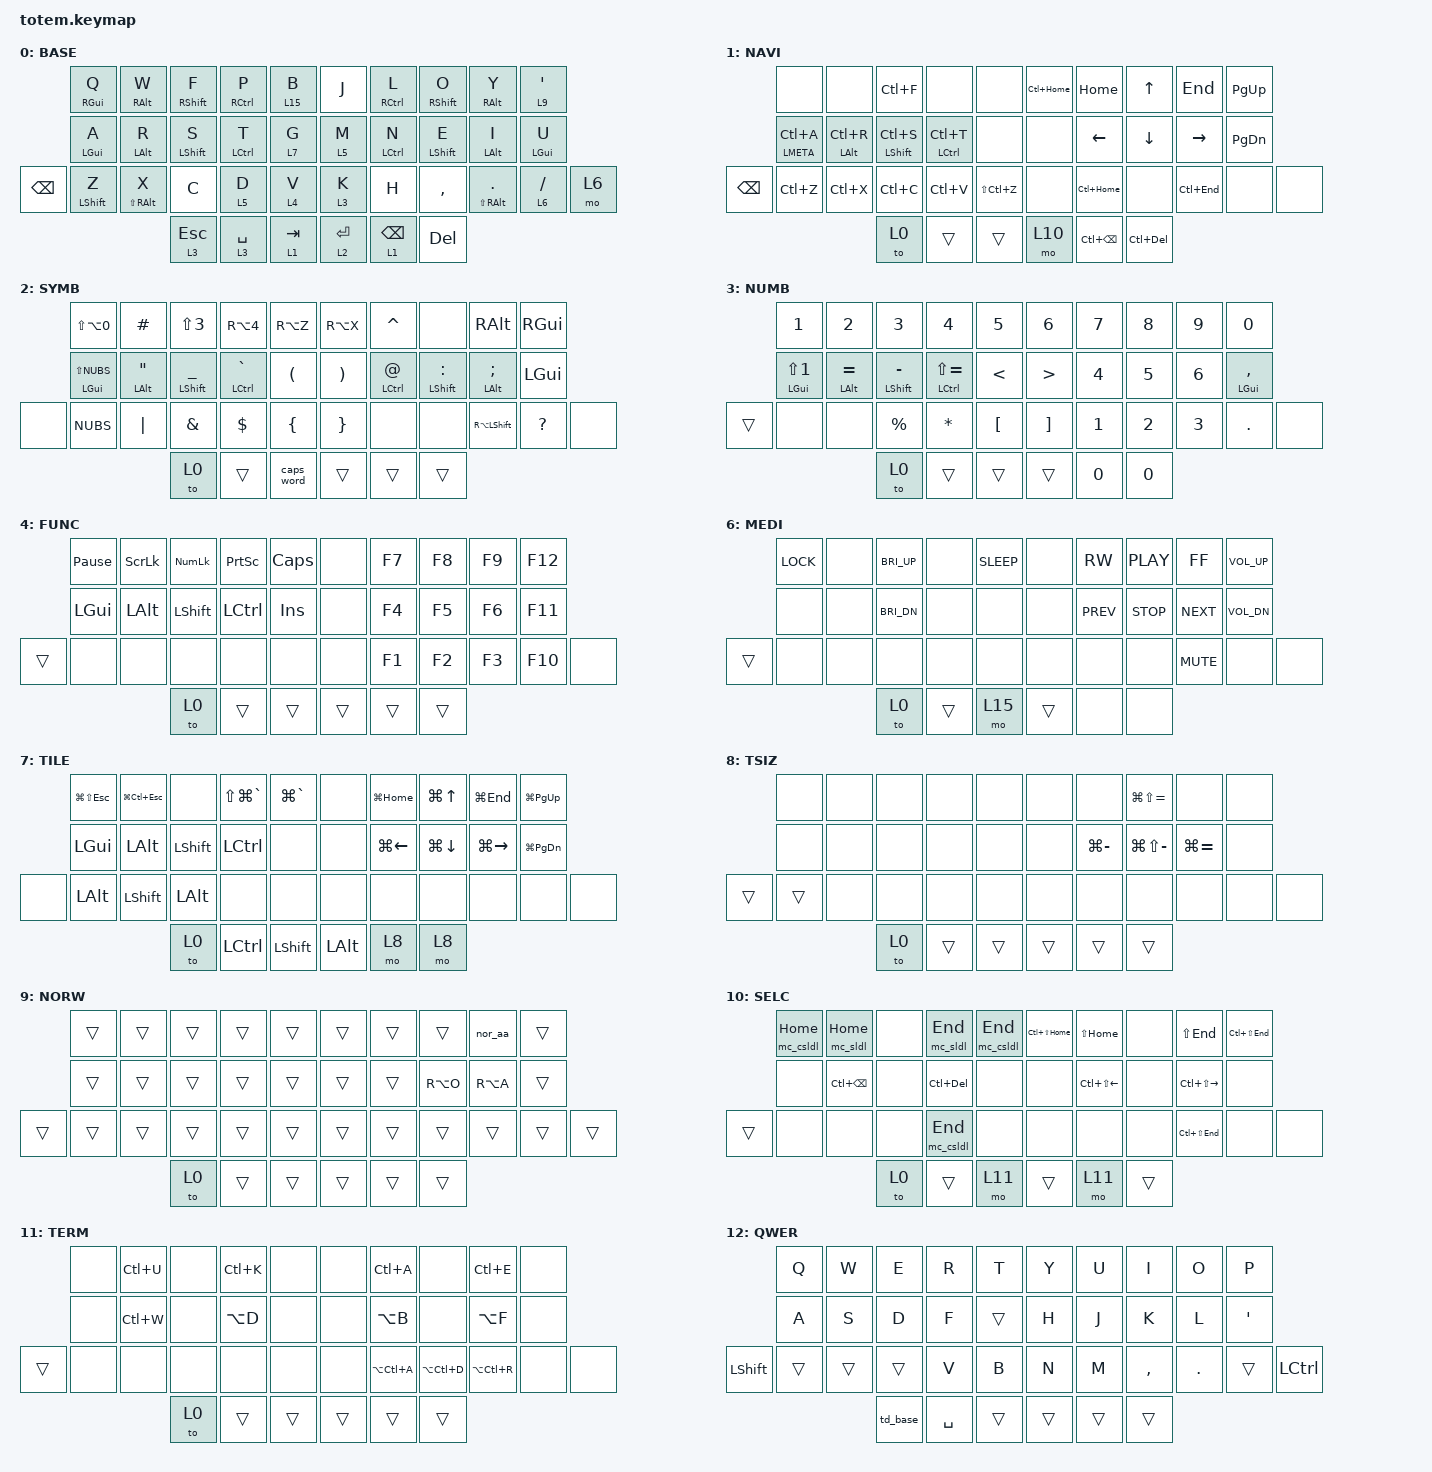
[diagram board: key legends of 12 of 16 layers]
//
//                                                        ▀▀▀▀▀     ▀▀▀▀▀          ▀▀█▀▀
//                                                        ▄▀▀▀▄  ▄  ▄▀▀▀▄  ▄  ▄▀▀▀▄  █  ▄▀▀▀▄
//                                                        █   █  █  █   █  █  █   █  █  █   █
//                                                         ▀▀▀   █   ▀▀▀   █   ▀▀▀   ▀   ▀▀▀
//                                                               █      ▄▄▄█▄▄▄    █   █
//                                                               ▀      █  █  █     █▄█
//                                                             ▀▀▀▀▀    █  █  █      ▀
//                                                                      ▀  ▀  ▀
//
// ▄▄▄▄▄▄▄▄▄▄▄▄▄▄▄▄▄▄▄▄▄▄▄▄▄▄▄▄▄▄▄▄▄▄▄▄▄▄▄▄▄▄▄▄▄▄▄▄▄▄▄▄▄▄▄▄▄▄▄▄▄▄▄▄▄▄▄▄▄▄▄▄▄▄▄▄▄▄▄▄▄▄▄▄▄▄▄▄▄▄▄▄▄▄▄▄▄▄▄▄▄▄▄▄▄▄▄▄▄▄▄▄▄▄▄▄▄▄▄▄▄▄▄▄▄▄▄▄▄▄▄▄▄▄▄▄▄▄▄▄▄▄▄▄▄▄▄▄▄

#include <behaviors.dtsi>
#include <dt-bindings/zmk/bt.h>
#include <dt-bindings/zmk/keys.h>
#include <dt-bindings/zmk/outputs.h>

#define BASE 0
#define NAVI 1
#define SYMB 2
#define NUMB 3
#define FUNC 4
#define CODE 5
#define MEDI 6
#define TILE 7
#define TSIZ 8
#define NORW 9
#define SELC 10
#define TERM 11
#define QWER 12
#define GAME 13
#define CSPL 14
#define BLUE 15

&mt {
    //   retro-tap;

    quick-tap-ms = <325>;
    global-quick-tap;
    flavor = "tap-preferred";
    tapping-term-ms = <250>;
    require-prior-idle-ms = <125>;
};

&lt {
    tapping-term-ms = <150>;
    quick-tap-ms = <225>;
};

/ {
    behaviors {
        hml: homerow_left {
            compatible = "zmk,behavior-hold-tap";
            #binding-cells = <2>;
            tapping-term-ms = <100>;
            quick-tap-ms = <200>;
            flavor = "tap-unless-interrupted";

            //      flavor = "tap-preferred";

            bindings = <&kp>, <&kp>;

            hold-trigger-key-positions = <5 6 7 8 9 15 16 17 18 19 26 27 28 29 30 31 35 36 37>;
        };

        hmr: homerow_right {
            compatible = "zmk,behavior-hold-tap";
            #binding-cells = <2>;
            tapping-term-ms = <150>;
            quick-tap-ms = <0>;
            flavor = "tap-preferred";
            bindings = <&kp>, <&kp>;

            hold-trigger-key-positions = <0 1 2 3 4 10 11 12 13 14 20 21 22 23 24 25 32 33 34>;
        };

        td_lcsh: tap_shift_lock {
            compatible = "zmk,behavior-tap-dance";
            #binding-cells = <0>;
            tapping-term-ms = <200>;
            bindings = <&mo 6>, <&kp K_LOCK>;
        };

        mt_split: mod_tap_split {
            compatible = "zmk,behavior-hold-tap";
            label = "MT_SPLIT";
            #binding-cells = <2>;
            tapping-term-ms = <200>;
            quick-tap-ms = <0>;
            flavor = "hold-preferred";
            bindings = <&codspl>, <&kp>;
        };

        td_base: tap_dance_base_esc {
            compatible = "zmk,behavior-tap-dance";
            #binding-cells = <0>;
            tapping-term-ms = <200>;
            bindings = <&kp ESC>, <&to 0>;
        };
    };

    macros {
        vsc: macro_vscode_cmd {
            #binding-cells = <1>;
            compatible = "zmk,behavior-macro-one-param";
            bindings =
                <&macro_tap>,
                <&kp LC(K) &macro_param_1to1>,
                <&macro_tap>,
                <&kp MACRO_PLACEHOLDER>;
        };

        codspl: macro_vscode_split {
            #binding-cells = <1>;
            compatible = "zmk,behavior-macro-one-param";
            bindings =
                <&macro_tap>,
                <&kp LC(K) &macro_param_1to1>,
                <&macro_tap>,
                <&kp MACRO_PLACEHOLDER>;
        };

        mc_rm2: macro_rmeta2 {
            compatible = "zmk,behavior-macro-two-param";
            #binding-cells = <2>;
            bindings =
                <&macro_press>,
                <&kp RGUI &macro_param_1to1>,
                <&macro_tap>,
                <&kp MACRO_PLACEHOLDER>,
                <&macro_release>,
                <&kp RGUI &macro_param_2to1>,
                <&macro_tap>,
                <&kp MACRO_PLACEHOLDER>;
        };

        mc_sldl: macro_select_delete {
            compatible = "zmk,behavior-macro-one-param";
            #binding-cells = <1>;
            bindings =
                <&macro_press>,
                <&kp LSHFT &macro_param_1to1>,
                <&macro_tap>,
                <&kp MACRO_PLACEHOLDER>,
                <&macro_release>,
                <&kp LSHFT>,
                <&macro_tap>,
                <&kp DEL>;
        };

        mc_csldl: macro_ctrsel_del {
            compatible = "zmk,behavior-macro-one-param";
            #binding-cells = <1>;
            bindings =
                <&macro_press>,
                <&kp LSHFT>,
                <&macro_press>,
                <&kp LCTRL &macro_param_1to1>,
                <&macro_tap>,
                <&kp MACRO_PLACEHOLDER>,
                <&macro_release>,
                <&kp LCTRL>,
                <&macro_release>,
                <&kp LSHFT>,
                <&macro_tap>,
                <&kp DEL>;
        };

        nor_aa: nor_aa {
            compatible = "zmk,behavior-macro";
            #binding-cells = <0>;
            bindings = <&macro_tap>, <&kp LS(RA(LEFT_BRACKET)) &kp A>;

            label = "NOR_AA";
        };
    };

    combos {
        compatible = "zmk,combos";

        combo_esc {
            bindings = <&kp ESC>;
            key-positions = <0 1>;
        };
    };

    keymap {
        compatible = "zmk,keymap";

        // ▄▄▄▄▄▄▄▄▄▄▄▄▄▄▄▄▄▄▄▄▄▄▄▄▄▄▄▄▄▄▄▄▄▄▄▄▄▄▄▄▄▄▄▄▄▄▄▄▄▄▄▄▄▄▄▄▄▄▄▄▄▄▄▄▄▄▄▄▄▄▄▄▄▄▄▄▄▄▄▄▄▄▄▄▄▄▄▄▄▄▄▄▄▄▄▄▄▄▄▄▄▄▄▄▄▄▄▄▄▄▄▄▄▄▄▄▄▄▄▄▄▄▄▄▄▄▄▄▄▄▄▄▄▄▄▄▄▄▄▄▄▄▄▄▄▄▄▄▄

        base_layer {
            // ┏━━━━━━━━━━━━━━━━━━━━━━━━━━━━━━━━━━━━━━━┓

            label = "BASE";

            // ┗━━━━━━━━━━━━━━━━━━━━━━━━━━━━━━━━━━━━━━━┛
            //             ┏━━━━━━━━━━━┳━━━━━━━━━━━┳━━━━━━━━━━━┳━━━━━━━━━━━┳━━━━━━━━━━━┓   ┏━━━━━━━━━━━┳━━━━━━━━━━━┳━━━━━━━━━━━┳━━━━━━━━━━━┳━━━━━━━━━━━┓
            //             ┃     Q     ┃     W     ┃     F     ┃     P     ┃     B     ┃   ┃     J     ┃     L     ┃     O     ┃     Y     ┃     '     ┃
            //             ┣━━━━━━━━━━━╋━━━━━━━━━━━╋━━━━━━━━━━━╋━━━━━━━━━━━╋━━━━━━━━━━━┫   ┣━━━━━━━━━━━╋━━━━━━━━━━━╋━━━━━━━━━━━╋━━━━━━━━━━━╋━━━━━━━━━━━┫
            //             ┃     A     ┃     R     ┃     S     ┃     T     ┃     G     ┃   ┃     M     ┃     N     ┃     E     ┃     I     ┃     U     ┃
            // ┏━━━━━━━━━━━╋━━━━━━━━━━━╋━━━━━━━━━━━╋━━━━━━━━━━━╋━━━━━━━━━━━╋━━━━━━━━━━━┫   ┣━━━━━━━━━━━╋━━━━━━━━━━━╋━━━━━━━━━━━╋━━━━━━━━━━━╋━━━━━━━━━━━╋━━━━━━━━━━━┓
            // ┃    BSPC   ┃     Z     ┃     X     ┃     C     ┃     D     ┃     V     ┃   ┃     K     ┃     H     ┃     ,     ┃     .     ┃     /     ┃           ┃
            // ┗━━━━━━━━━━━┻━━━━━━━━━━━┻━━━━━━━━━━━╋━━━━━━━━━━━╋━━━━━━━━━━━╋━━━━━━━━━━━┫   ┣━━━━━━━━━━━╋━━━━━━━━━━━╋━━━━━━━━━━━╋━━━━━━━━━━━┻━━━━━━━━━━━┻━━━━━━━━━━━┛
            //                                     ┃    ESC    ┃    SPC    ┃    TAB    ┃   ┃   ENTER   ┃    BSPC   ┃    DEL    ┃
            //                                     ┗━━━━━━━━━━━┻━━━━━━━━━━━┻━━━━━━━━━━━┛   ┗━━━━━━━━━━━┻━━━━━━━━━━━┻━━━━━━━━━━━┛
            //             ┏━━━━━━━━━━━┳━━━━━━━━━━━┳━━━━━━━━━━━┳━━━━━━━━━━━┳━━━━━━━━━━━┓   ┏━━━━━━━━━━━┳━━━━━━━━━━━┳━━━━━━━━━━━┳━━━━━━━━━━━┳━━━━━━━━━━━┓
            //             ┃   RMETA   ┃   RALT    ┃   RSHFT   ┃   RCTRL   ┃           ┃   ┃           ┃   RCTRL   ┃   RSHFT   ┃    RALT   ┃    NORW   ┃
            //             ┣━━━━━━━━━━━╋━━━━━━━━━━━╋━━━━━━━━━━━╋━━━━━━━━━━━╋━━━━━━━━━━━┫   ┣━━━━━━━━━━━╋━━━━━━━━━━━╋━━━━━━━━━━━╋━━━━━━━━━━━╋━━━━━━━━━━━┫
            //             ┃   LMETA   ┃   LALT   ┃   LSHFT   ┃   LCTRL    ┃    CODE   ┃   ┃   CODE    ┃   LCTRL    ┃   LSHFT   ┃   LALT   ┃   LMETA   ┃
            // ┏━━━━━━━━━━━╋━━━━━━━━━━━╋━━━━━━━━━━━╋━━━━━━━━━━━╋━━━━━━━━━━━╋━━━━━━━━━━━┫   ┣━━━━━━━━━━━╋━━━━━━━━━━━╋━━━━━━━━━━━╋━━━━━━━━━━━╋━━━━━━━━━━━╋━━━━━━━━━━━┓
            // ┃   LSHFT   ┃           ┃   COMP    ┃           ┃   TILE    ┃    FUN    ┃   ┃           ┃           ┃           ┃    COMP   ┃           ┃   MEDI    ┃
            // ┗━━━━━━━━━━━┻━━━━━━━━━━━┻━━━━━━━━━━━╋━━━━━━━━━━━╋━━━━━━━━━━━╋━━━━━━━━━━━┫   ┣━━━━━━━━━━━╋━━━━━━━━━━━╋━━━━━━━━━━━╋━━━━━━━━━━━┻━━━━━━━━━━━┻━━━━━━━━━━━┛
            //                                     ┃           ┃    NUM    ┃    NAV    ┃   ┃    SYM    ┃   LSHFT   ┃           ┃
            //                                     ┗━━━━━━━━━━━┻━━━━━━━━━━━┻━━━━━━━━━━━┛   ┗━━━━━━━━━━━┻━━━━━━━━━━━┻━━━━━━━━━━━┛

            bindings = <
               &mt RGUI Q        &mt RALT W      &mt RSHFT F   &mt RCTRL P  &lt 15 B     &kp J      &mt RCTRL L      &mt RSHFT O  &mt RALT Y        &lt 9 SQT
               &mt LGUI A        &mt LALT R      &mt LSHFT S   &mt LCTRL T  &lt 7 G      &lt 5 M    &mt LCTRL N      &mt LSHFT E  &mt LALT I        &mt LGUI U
&kp BACKSPACE  &mt LEFT_SHIFT Z  &mt LS(RALT) X  &kp C         &lt 5 D      &lt 4 V      &lt 3 K    &kp H            &kp COMMA    &mt LS(RALT) DOT  &lt 6 FSLH  &mo 6
                                                 &lt 3 ESCAPE  &lt 3 SPACE  &lt 1 TAB    &lt 2 RET  &lt 1 BACKSPACE  &kp DEL
            >;
        };

        // ▄▄▄▄▄▄▄▄▄▄▄▄▄▄▄▄▄▄▄▄▄▄▄▄▄▄▄▄▄▄▄▄▄▄▄▄▄▄▄▄▄▄▄▄▄▄▄▄▄▄▄▄▄▄▄▄▄▄▄▄▄▄▄▄▄▄▄▄▄▄▄▄▄▄▄▄▄▄▄▄▄▄▄▄▄▄▄▄▄▄▄▄▄▄▄▄▄▄▄▄▄▄▄▄▄▄▄▄▄▄▄▄▄▄▄▄▄▄▄▄▄▄▄▄▄▄▄▄▄▄▄▄▄▄▄▄▄▄▄▄▄▄▄▄▄▄▄▄▄

        nav_layer {
            // ┏━━━━━━━━━━━━━━━━━━━━━━━━━━━━━━━━━━━━━━━┓

            label = "NAVI";

            // ┗━━━━━━━━━━━━━━━━━━━━━━━━━━━━━━━━━━━━━━━┛
            //             ┏━━━━━━━━━━━┳━━━━━━━━━━━┳━━━━━━━━━━━┳━━━━━━━━━━━┳━━━━━━━━━━━┓   ┏━━━━━━━━━━━┳━━━━━━━━━━━┳━━━━━━━━━━━┳━━━━━━━━━━━┳━━━━━━━━━━━┓
            //             ┃           ┃           ┃    FIND   ┃           ┃           ┃   ┃    TOP    ┃   HOME    ┃    UP     ┃   END     ┃   PG_UP   ┃
            //             ┣━━━━━━━━━━━╋━━━━━━━━━━━╋━━━━━━━━━━━╋━━━━━━━━━━━╋━━━━━━━━━━━┫   ┣━━━━━━━━━━━╋━━━━━━━━━━━╋━━━━━━━━━━━╋━━━━━━━━━━━╋━━━━━━━━━━━┫
            //             ┃   SELECT  ┃   RELOAD  ┃    SAVE   ┃  NEW TAB  ┃ CAPS WORD ┃   ┃           ┃   LEFT    ┃    DOWN   ┃   RIGHT   ┃   PG_DN   ┃
            // ┏━━━━━━━━━━━╋━━━━━━━━━━━╋━━━━━━━━━━━╋━━━━━━━━━━━╋━━━━━━━━━━━╋━━━━━━━━━━━┫   ┣━━━━━━━━━━━╋━━━━━━━━━━━╋━━━━━━━━━━━╋━━━━━━━━━━━╋━━━━━━━━━━━╋━━━━━━━━━━━┓
            // ┃ BACKSPACE ┃    UNDO   ┃    CUT    ┃   COPY    ┃   PASTE   ┃   REDO    ┃   ┃           ┃    TOP    ┃           ┃   BTTM    ┃           ┃           ┃
            // ┗━━━━━━━━━━━┻━━━━━━━━━━━┻━━━━━━━━━━━╋━━━━━━━━━━━╋━━━━━━━━━━━╋━━━━━━━━━━━┫   ┣━━━━━━━━━━━╋━━━━━━━━━━━╋━━━━━━━━━━━╋━━━━━━━━━━━┻━━━━━━━━━━━┻━━━━━━━━━━━┛
            //                                     ┃           ┃           ┃           ┃   ┃   SELECT  ┃^BACKSPACE ┃   ^ DEL   ┃
            //                                     ┗━━━━━━━━━━━┻━━━━━━━━━━━┻━━━━━━━━━━━┛   ┗━━━━━━━━━━━┻━━━━━━━━━━━┻━━━━━━━━━━━┛

            bindings = <
          &none            &none           &kp LC(F)        &none            &none            &kp LC(HOME)  &kp HOME      &kp UP       &kp END      &kp PG_UP
          &mt LMETA LC(A)  &mt LALT LC(R)  &mt LSHFT LC(S)  &mt LCTRL LC(T)  &none            &none         &kp LEFT      &kp DOWN     &kp RIGHT    &kp PG_DN
&kp BSPC  &kp LC(Z)        &kp LC(X)       &kp LC(C)        &kp LC(V)        &kp LS(LC(Z))    &none         &kp LC(HOME)  &none        &kp LC(END)  &none      &none
                                           &to 0            &trans           &trans           &mo 10        &kp LC(BSPC)  &kp LC(DEL)
            >;
        };

        // ▄▄▄▄▄▄▄▄▄▄▄▄▄▄▄▄▄▄▄▄▄▄▄▄▄▄▄▄▄▄▄▄▄▄▄▄▄▄▄▄▄▄▄▄▄▄▄▄▄▄▄▄▄▄▄▄▄▄▄▄▄▄▄▄▄▄▄▄▄▄▄▄▄▄▄▄▄▄▄▄▄▄▄▄▄▄▄▄▄▄▄▄▄▄▄▄▄▄▄▄▄▄▄▄▄▄▄▄▄▄▄▄▄▄▄▄▄▄▄▄▄▄▄▄▄▄▄▄▄▄▄▄▄▄▄▄▄▄▄▄▄▄▄▄▄▄▄▄▄

        symbol_layer {
            // ┏━━━━━━━━━━━━━━━━━━━━━━━━━━━━━━━━━━━━━━━┓

            label = "SYMB";

            // ┗━━━━━━━━━━━━━━━━━━━━━━━━━━━━━━━━━━━━━━━┛
            //             ┏━━━━━━━━━━━┳━━━━━━━━━━━┳━━━━━━━━━━━┳━━━━━━━━━━━┳━━━━━━━━━━━┓   ┏━━━━━━━━━━━┳━━━━━━━━━━━┳━━━━━━━━━━━┳━━━━━━━━━━━┳━━━━━━━━━━━┓
            //             ┃     °     ┃     #     ┃     £     ┃     ˆ     ┃     «     ┃   ┃     »     ┃           ┃           ┃           ┃           ┃
            //             ┣━━━━━━━━━━━╋━━━━━━━━━━━╋━━━━━━━━━━━╋━━━━━━━━━━━╋━━━━━━━━━━━┫   ┣━━━━━━━━━━━╋━━━━━━━━━━━╋━━━━━━━━━━━╋━━━━━━━━━━━╋━━━━━━━━━━━┫
            //             ┃     |     ┃     @     ┃     _     ┃     `     ┃     (     ┃   ┃     )     ┃     "     ┃     :     ┃     ;     ┃           ┃
            // ┏━━━━━━━━━━━╋━━━━━━━━━━━╋━━━━━━━━━━━╋━━━━━━━━━━━╋━━━━━━━━━━━╋━━━━━━━━━━━┫   ┣━━━━━━━━━━━╋━━━━━━━━━━━╋━━━━━━━━━━━╋━━━━━━━━━━━╋━━━━━━━━━━━╋━━━━━━━━━━━┓
            // ┃           ┃     \     ┃     ~     ┃     &     ┃     $     ┃     {     ┃   ┃     }     ┃           ┃           ┃           ┃     ?     ┃           ┃
            // ┗━━━━━━━━━━━┻━━━━━━━━━━━┻━━━━━━━━━━━╋━━━━━━━━━━━╋━━━━━━━━━━━╋━━━━━━━━━━━┫   ┣━━━━━━━━━━━╋━━━━━━━━━━━╋━━━━━━━━━━━╋━━━━━━━━━━━┻━━━━━━━━━━━┻━━━━━━━━━━━┛
            //                                     ┃           ┃           ┃           ┃   ┃           ┃           ┃           ┃
            //                                     ┗━━━━━━━━━━━┻━━━━━━━━━━━┻━━━━━━━━━━━┛   ┗━━━━━━━━━━━┻━━━━━━━━━━━┻━━━━━━━━━━━┛

            bindings = <
       &kp LS(LA(0))      &kp HASH      &kp LS(NUMBER_3)  &kp RA(NUMBER_4)  &kp RA(Z)     &kp RA(X)  &kp CARET     &none            &kp RALT       &kp RGUI
       &mt LGUI LS(NUBS)  &mt LALT DQT  &mt LSHFT UNDER   &mt LCTRL GRAVE   &kp LPAR      &kp RPAR   &mt LCTRL AT  &mt LSHFT COLON  &mt LALT SEMI  &kp LGUI
&none  &kp NUBS           &kp PIPE      &kp AMPS          &kp DLLR          &kp LBRC      &kp RBRC   &none         &none            &kp RA(LSHFT)  &kp QMARK  &none
                                        &to 0             &trans            &caps_word    &trans     &trans        &trans
            >;
        };

        // ▄▄▄▄▄▄▄▄▄▄▄▄▄▄▄▄▄▄▄▄▄▄▄▄▄▄▄▄▄▄▄▄▄▄▄▄▄▄▄▄▄▄▄▄▄▄▄▄▄▄▄▄▄▄▄▄▄▄▄▄▄▄▄▄▄▄▄▄▄▄▄▄▄▄▄▄▄▄▄▄▄▄▄▄▄▄▄▄▄▄▄▄▄▄▄▄▄▄▄▄▄▄▄▄▄▄▄▄▄▄▄▄▄▄▄▄▄▄▄▄▄▄▄▄▄▄▄▄▄▄▄▄▄▄▄▄▄▄▄▄▄▄▄▄▄▄▄▄▄

        number_layer {
            // ┏━━━━━━━━━━━━━━━━━━━━━━━━━━━━━━━━━━━━━━━┓

            label = "NUMB";

            // ┗━━━━━━━━━━━━━━━━━━━━━━━━━━━━━━━━━━━━━━━┛
            //             ┏━━━━━━━━━━━┳━━━━━━━━━━━┳━━━━━━━━━━━┳━━━━━━━━━━━┳━━━━━━━━━━━┓   ┏━━━━━━━━━━━┳━━━━━━━━━━━┳━━━━━━━━━━━┳━━━━━━━━━━━┳━━━━━━━━━━━┓
            //             ┃     1     ┃     2     ┃     3     ┃     4     ┃     5     ┃   ┃     6     ┃     7     ┃     8     ┃     9     ┃     0     ┃
            //             ┣━━━━━━━━━━━╋━━━━━━━━━━━╋━━━━━━━━━━━╋━━━━━━━━━━━╋━━━━━━━━━━━┫   ┣━━━━━━━━━━━╋━━━━━━━━━━━╋━━━━━━━━━━━╋━━━━━━━━━━━╋━━━━━━━━━━━┫
            //             ┃     !     ┃     =     ┃     -     ┃     +     ┃     <     ┃   ┃     >     ┃     4     ┃     5     ┃     6     ┃           ┃
            // ┏━━━━━━━━━━━╋━━━━━━━━━━━╋━━━━━━━━━━━╋━━━━━━━━━━━╋━━━━━━━━━━━╋━━━━━━━━━━━┫   ┣━━━━━━━━━━━╋━━━━━━━━━━━╋━━━━━━━━━━━╋━━━━━━━━━━━╋━━━━━━━━━━━╋━━━━━━━━━━━┓
            // ┃           ┃           ┃           ┃     %     ┃     *     ┃     [     ┃   ┃     ]     ┃     1     ┃     2     ┃     3     ┃     .     ┃     ,     ┃
            // ┗━━━━━━━━━━━┻━━━━━━━━━━━┻━━━━━━━━━━━╋━━━━━━━━━━━╋━━━━━━━━━━━╋━━━━━━━━━━━┫   ┣━━━━━━━━━━━╋━━━━━━━━━━━╋━━━━━━━━━━━╋━━━━━━━━━━━┻━━━━━━━━━━━┻━━━━━━━━━━━┛
            //                                     ┃           ┃           ┃           ┃   ┃           ┃     0     ┃     0     ┃
            //                                     ┗━━━━━━━━━━━┻━━━━━━━━━━━┻━━━━━━━━━━━┛   ┗━━━━━━━━━━━┻━━━━━━━━━━━┻━━━━━━━━━━━┛

            bindings = <
        &kp N1           &kp N2          &kp N3           &kp N4               &kp N5              &kp N6             &kp N7  &kp N8  &kp N9  &kp N0
        &mt LGUI LS(N1)  &mt LALT EQUAL  &mt LSHFT MINUS  &mt LCTRL LS(EQUAL)  &kp LT              &kp GT             &kp N4  &kp N5  &kp N6  &mt LGUI COMMA
&trans  &none            &none           &kp PERCENT      &kp STAR             &kp LEFT_BRACKET    &kp RIGHT_BRACKET  &kp N1  &kp N2  &kp N3  &kp DOT         &none
                                         &to 0            &trans               &trans              &trans             &kp N0  &kp N0
            >;
        };

        // ▄▄▄▄▄▄▄▄▄▄▄▄▄▄▄▄▄▄▄▄▄▄▄▄▄▄▄▄▄▄▄▄▄▄▄▄▄▄▄▄▄▄▄▄▄▄▄▄▄▄▄▄▄▄▄▄▄▄▄▄▄▄▄▄▄▄▄▄▄▄▄▄▄▄▄▄▄▄▄▄▄▄▄▄▄▄▄▄▄▄▄▄▄▄▄▄▄▄▄▄▄▄▄▄▄▄▄▄▄▄▄▄▄▄▄▄▄▄▄▄▄▄▄▄▄▄▄▄▄▄▄▄▄▄▄▄▄▄▄▄▄▄▄▄▄▄▄▄▄

        function_layer {
            // ┏━━━━━━━━━━━━━━━━━━━━━━━━━━━━━━━━━━━━━━━┓

            label = "FUNC";

            // ┗━━━━━━━━━━━━━━━━━━━━━━━━━━━━━━━━━━━━━━━┛
            //             ┏━━━━━━━━━━━┳━━━━━━━━━━━┳━━━━━━━━━━━┳━━━━━━━━━━━┳━━━━━━━━━━━┓   ┏━━━━━━━━━━━┳━━━━━━━━━━━┳━━━━━━━━━━━┳━━━━━━━━━━━┳━━━━━━━━━━━┓
            //             ┃   Pause   ┃   Scroll  ┃  Numlock  ┃   Print   ┃    Caps   ┃   ┃           ┃    F7     ┃    F8     ┃    F9     ┃    F12    ┃
            //             ┣━━━━━━━━━━━╋━━━━━━━━━━━╋━━━━━━━━━━━╋━━━━━━━━━━━╋━━━━━━━━━━━┫   ┣━━━━━━━━━━━╋━━━━━━━━━━━╋━━━━━━━━━━━╋━━━━━━━━━━━╋━━━━━━━━━━━┫
            //             ┃   META    ┃    ALT    ┃   SHIFT   ┃   CTRL    ┃    Ins    ┃   ┃           ┃    F4     ┃    F5     ┃    F6     ┃    F11    ┃
            // ┏━━━━━━━━━━━╋━━━━━━━━━━━╋━━━━━━━━━━━╋━━━━━━━━━━━╋━━━━━━━━━━━╋━━━━━━━━━━━┫   ┣━━━━━━━━━━━╋━━━━━━━━━━━╋━━━━━━━━━━━╋━━━━━━━━━━━╋━━━━━━━━━━━╋━━━━━━━━━━━┓
            // ┃           ┃           ┃           ┃           ┃           ┃           ┃   ┃           ┃    F1     ┃    F2     ┃    F3     ┃    F10    ┃           ┃
            // ┗━━━━━━━━━━━┻━━━━━━━━━━━┻━━━━━━━━━━━╋━━━━━━━━━━━╋━━━━━━━━━━━╋━━━━━━━━━━━┫   ┣━━━━━━━━━━━╋━━━━━━━━━━━╋━━━━━━━━━━━╋━━━━━━━━━━━┻━━━━━━━━━━━┻━━━━━━━━━━━┛
            //                                     ┃           ┃           ┃           ┃   ┃           ┃           ┃           ┃
            //                                     ┗━━━━━━━━━━━┻━━━━━━━━━━━┻━━━━━━━━━━━┛   ┗━━━━━━━━━━━┻━━━━━━━━━━━┻━━━━━━━━━━━┛

            bindings = <
        &kp PAUSE_BREAK  &kp SLCK  &kp KP_NUM  &kp PSCRN  &kp CAPS    &none   &kp F7  &kp F8  &kp F9  &kp F12
        &kp LGUI         &kp LALT  &kp LSHFT   &kp LCTRL  &kp INS     &none   &kp F4  &kp F5  &kp F6  &kp F11
&trans  &none            &none     &none       &none      &none       &none   &kp F1  &kp F2  &kp F3  &kp F10  &none
                                   &to 0       &trans     &trans      &trans  &trans  &trans
            >;
        };

        // ▄▄▄▄▄▄▄▄▄▄▄▄▄▄▄▄▄▄▄▄▄▄▄▄▄▄▄▄▄▄▄▄▄▄▄▄▄▄▄▄▄▄▄▄▄▄▄▄▄▄▄▄▄▄▄▄▄▄▄▄▄▄▄▄▄▄▄▄▄▄▄▄▄▄▄▄▄▄▄▄▄▄▄▄▄▄▄▄▄▄▄▄▄▄▄▄▄▄▄▄▄▄▄▄▄▄▄▄▄▄▄▄▄▄▄▄▄▄▄▄▄▄▄▄▄▄▄▄▄▄▄▄▄▄▄▄▄▄▄▄▄▄▄▄▄▄▄▄▄

        code_layer {
            // ┏━━━━━━━━━━━━━━━━━━━━━━━━━━━━━━━━━━━━━━━┓

            label = "CODE";

            // ┗━━━━━━━━━━━━━━━━━━━━━━━━━━━━━━━━━━━━━━━┛
            //             ┏━━━━━━━━━━━┳━━━━━━━━━━━┳━━━━━━━━━━━┳━━━━━━━━━━━┳━━━━━━━━━━━┓   ┏━━━━━━━━━━━┳━━━━━━━━━━━┳━━━━━━━━━━━┳━━━━━━━━━━━┳━━━━━━━━━━━┓
            //             ┃   QWERTY  ┃   GAME    ┃           ┃           ┃           ┃   ┃   IMPL    ┃           ┃  DUPE UP  ┃           ┃           ┃
            //             ┣━━━━━━━━━━━╋━━━━━━━━━━━╋━━━━━━━━━━━╋━━━━━━━━━━━╋━━━━━━━━━━━┫   ┣━━━━━━━━━━━╋━━━━━━━━━━━╋━━━━━━━━━━━╋━━━━━━━━━━━╋━━━━━━━━━━━┫
            //             ┃           ┃           ┃   SAVE    ┃   SPLIT   ┃           ┃   ┃           ┃           ┃ DUPE DOWN ┃           ┃           ┃
            // ┏━━━━━━━━━━━╋━━━━━━━━━━━╋━━━━━━━━━━━╋━━━━━━━━━━━╋━━━━━━━━━━━╋━━━━━━━━━━━┫   ┣━━━━━━━━━━━╋━━━━━━━━━━━╋━━━━━━━━━━━╋━━━━━━━━━━━╋━━━━━━━━━━━╋━━━━━━━━━━━┓
            // ┃  SIDEBAR  ┃    ZEN    ┃           ┃           ┃ Move Term ┃  Terminal ┃   ┃           ┃           ┃           ┃           ┃           ┃  COMMENT  ┃
            // ┗━━━━━━━━━━━┻━━━━━━━━━━━┻━━━━━━━━━━━╋━━━━━━━━━━━╋━━━━━━━━━━━╋━━━━━━━━━━━┫   ┣━━━━━━━━━━━╋━━━━━━━━━━━╋━━━━━━━━━━━╋━━━━━━━━━━━┻━━━━━━━━━━━┻━━━━━━━━━━━┛
            //                                     ┃           ┃           ┃ BLUETOOTH ┃   ┃   LAUNCH  ┃    RUN    ┃           ┃
            //                                     ┗━━━━━━━━━━━┻━━━━━━━━━━━┻━━━━━━━━━━━┛   ┗━━━━━━━━━━━┻━━━━━━━━━━━┻━━━━━━━━━━━┛

            bindings = <
              &to 12  &to 13  &none   &none              &none                &kp LS(F12)    &none      &kp LA(LC(LS(UP)))    &none  &none
              &none   &none   &vsc S  &trans             &kp LS(LA(LC(E)))    &none          &none      &kp LA(LC(LS(DOWN)))  &none  &none
&kp LC(BSLH)  &vsc Z  &none   &mo 14  &kp LA(LC(LS(E)))  &kp LC(GRAVE)        &kp LC(LS(K))  &none      &none                 &none  &kp LC(FSLH)  &kp LC(FSLH)
                              &to 0   &trans             &mo 14               &kp LA(F2)     &kp LG(A)  &trans
            >;
        };

        // ▄▄▄▄▄▄▄▄▄▄▄▄▄▄▄▄▄▄▄▄▄▄▄▄▄▄▄▄▄▄▄▄▄▄▄▄▄▄▄▄▄▄▄▄▄▄▄▄▄▄▄▄▄▄▄▄▄▄▄▄▄▄▄▄▄▄▄▄▄▄▄▄▄▄▄▄▄▄▄▄▄▄▄▄▄▄▄▄▄▄▄▄▄▄▄▄▄▄▄▄▄▄▄▄▄▄▄▄▄▄▄▄▄▄▄▄▄▄▄▄▄▄▄▄▄▄▄▄▄▄▄▄▄▄▄▄▄▄▄▄▄▄▄▄▄▄▄▄▄

        media_layer {
            // ┏━━━━━━━━━━━━━━━━━━━━━━━━━━━━━━━━━━━━━━━┓

            label = "MEDI";

            // ┗━━━━━━━━━━━━━━━━━━━━━━━━━━━━━━━━━━━━━━━┛
            //             ┏━━━━━━━━━━━┳━━━━━━━━━━━┳━━━━━━━━━━━┳━━━━━━━━━━━┳━━━━━━━━━━━┓   ┏━━━━━━━━━━━┳━━━━━━━━━━━┳━━━━━━━━━━━┳━━━━━━━━━━━┳━━━━━━━━━━━┓
            //             ┃    LOCK   ┃           ┃  BRIGHT+  ┃           ┃   SLEEP   ┃   ┃           ┃   REWIND  ┃    PLAY   ┃  FORWARD  ┃    VOL+   ┃
            //             ┣━━━━━━━━━━━╋━━━━━━━━━━━╋━━━━━━━━━━━╋━━━━━━━━━━━╋━━━━━━━━━━━┫   ┣━━━━━━━━━━━╋━━━━━━━━━━━╋━━━━━━━━━━━╋━━━━━━━━━━━╋━━━━━━━━━━━┫
            //             ┃           ┃           ┃  BRIGHT-  ┃           ┃           ┃   ┃           ┃   LAST    ┃    STOP   ┃    NEXT   ┃    VOL-   ┃
            // ┏━━━━━━━━━━━╋━━━━━━━━━━━╋━━━━━━━━━━━╋━━━━━━━━━━━╋━━━━━━━━━━━╋━━━━━━━━━━━┫   ┣━━━━━━━━━━━╋━━━━━━━━━━━╋━━━━━━━━━━━╋━━━━━━━━━━━╋━━━━━━━━━━━╋━━━━━━━━━━━┓
            // ┃           ┃           ┃           ┃           ┃           ┃           ┃   ┃           ┃           ┃           ┃    MUTE   ┃           ┃           ┃
            // ┗━━━━━━━━━━━┻━━━━━━━━━━━┻━━━━━━━━━━━╋━━━━━━━━━━━╋━━━━━━━━━━━╋━━━━━━━━━━━┫   ┣━━━━━━━━━━━╋━━━━━━━━━━━╋━━━━━━━━━━━╋━━━━━━━━━━━┻━━━━━━━━━━━┻━━━━━━━━━━━┛
            //                                     ┃           ┃           ┃ BLUETOOTH ┃   ┃           ┃           ┃           ┃
            //                                     ┗━━━━━━━━━━━┻━━━━━━━━━━━┻━━━━━━━━━━━┛   ┗━━━━━━━━━━━┻━━━━━━━━━━━┻━━━━━━━━━━━┛

            bindings = <
        &kp K_LOCK  &none  &kp C_BRI_UP  &none   &kp C_SLEEP    &none   &kp C_RW    &kp C_PLAY  &kp C_FF    &kp K_VOL_UP
        &none       &none  &kp C_BRI_DN  &none   &none          &none   &kp C_PREV  &kp C_STOP  &kp C_NEXT  &kp K_VOL_DN
&trans  &none       &none  &none         &none   &none          &none   &none       &none       &kp C_MUTE  &none         &none
                           &to 0         &trans  &mo 15         &trans  &none       &none
            >;
        };

        // ▄▄▄▄▄▄▄▄▄▄▄▄▄▄▄▄▄▄▄▄▄▄▄▄▄▄▄▄▄▄▄▄▄▄▄▄▄▄▄▄▄▄▄▄▄▄▄▄▄▄▄▄▄▄▄▄▄▄▄▄▄▄▄▄▄▄▄▄▄▄▄▄▄▄▄▄▄▄▄▄▄▄▄▄▄▄▄▄▄▄▄▄▄▄▄▄▄▄▄▄▄▄▄▄▄▄▄▄▄▄▄▄▄▄▄▄▄▄▄▄▄▄▄▄▄▄▄▄▄▄▄▄▄▄▄▄▄▄▄▄▄▄▄▄▄▄▄▄▄

        tiling_layer {
            // ┏━━━━━━━━━━━━━━━━━━━━━━━━━━━━━━━━━━━━━━━┓

            label = "TILE";

            // ┗━━━━━━━━━━━━━━━━━━━━━━━━━━━━━━━━━━━━━━━┛
            //             ┏━━━━━━━━━━━┳━━━━━━━━━━━┳━━━━━━━━━━━┳━━━━━━━━━━━┳━━━━━━━━━━━┓   ┏━━━━━━━━━━━┳━━━━━━━━━━━┳━━━━━━━━━━━┳━━━━━━━━━━━┳━━━━━━━━━━━┓
            //             ┃  SCRATCH  ┃ SCRTCHALL ┃           ┃           ┃  META `   ┃   ┃           ┃ META HOME ┃  META UP  ┃ META END  ┃ META PGUP ┃
            //             ┣━━━━━━━━━━━╋━━━━━━━━━━━╋━━━━━━━━━━━╋━━━━━━━━━━━╋━━━━━━━━━━━┫   ┣━━━━━━━━━━━╋━━━━━━━━━━━╋━━━━━━━━━━━╋━━━━━━━━━━━╋━━━━━━━━━━━┫
            //             ┃           ┃           ┃           ┃           ┃ META SF ` ┃   ┃           ┃ META LEFT ┃ META DOWN ┃ METARIGHT ┃ META PGDN ┃
            // ┏━━━━━━━━━━━╋━━━━━━━━━━━╋━━━━━━━━━━━╋━━━━━━━━━━━╋━━━━━━━━━━━╋━━━━━━━━━━━┫   ┣━━━━━━━━━━━╋━━━━━━━━━━━╋━━━━━━━━━━━╋━━━━━━━━━━━╋━━━━━━━━━━━╋━━━━━━━━━━━┓
            // ┃           ┃           ┃           ┃           ┃           ┃           ┃   ┃           ┃           ┃           ┃           ┃           ┃           ┃
            // ┗━━━━━━━━━━━┻━━━━━━━━━━━┻━━━━━━━━━━━╋━━━━━━━━━━━╋━━━━━━━━━━━╋━━━━━━━━━━━┫   ┣━━━━━━━━━━━╋━━━━━━━━━━━╋━━━━━━━━━━━╋━━━━━━━━━━━┻━━━━━━━━━━━┻━━━━━━━━━━━┛
            //                                     ┃           ┃   CTRL    ┃   SHIFT   ┃   ┃    ALT    ┃   RESIZE  ┃           ┃
            //                                     ┗━━━━━━━━━━━┻━━━━━━━━━━━┻━━━━━━━━━━━┛   ┗━━━━━━━━━━━┻━━━━━━━━━━━┻━━━━━━━━━━━┛

            bindings = <
       &kp LG(LS(ESC))  &kp LG(LC(ESC))  &none         &kp LS(LG(GRAVE))  &kp LG(GRAVE)    &none     &kp LG(HOME)  &kp LG(UP)    &kp LG(END)    &kp LG(PG_UP)
       &kp LGUI         &kp LALT         &kp LSHFT     &kp LCTRL          &none            &none     &kp LG(LEFT)  &kp LG(DOWN)  &kp LG(RIGHT)  &kp LG(PG_DN)
&none  &kp LALT         &kp LEFT_SHIFT   &kp LEFT_ALT  &none              &none            &none     &none         &none         &none          &none          &none
                                         &to 0         &kp LCTRL          &kp LSHFT        &kp LALT  &mo 8         &mo 8
            >;
        };

        // ▄▄▄▄▄▄▄▄▄▄▄▄▄▄▄▄▄▄▄▄▄▄▄▄▄▄▄▄▄▄▄▄▄▄▄▄▄▄▄▄▄▄▄▄▄▄▄▄▄▄▄▄▄▄▄▄▄▄▄▄▄▄▄▄▄▄▄▄▄▄▄▄▄▄▄▄▄▄▄▄▄▄▄▄▄▄▄▄▄▄▄▄▄▄▄▄▄▄▄▄▄▄▄▄▄▄▄▄▄▄▄▄▄▄▄▄▄▄▄▄▄▄▄▄▄▄▄▄▄▄▄▄▄▄▄▄▄▄▄▄▄▄▄▄▄▄▄▄▄

        tilesize_layer {
            // ┏━━━━━━━━━━━━━━━━━━━━━━━━━━━━━━━━━━━━━━━┓

            label = "TSIZ";

            // ┗━━━━━━━━━━━━━━━━━━━━━━━━━━━━━━━━━━━━━━━┛
            //             ┏━━━━━━━━━━━┳━━━━━━━━━━━┳━━━━━━━━━━━┳━━━━━━━━━━━┳━━━━━━━━━━━┓   ┏━━━━━━━━━━━┳━━━━━━━━━━━┳━━━━━━━━━━━┳━━━━━━━━━━━┳━━━━━━━━━━━┓
            //             ┃           ┃           ┃           ┃           ┃           ┃   ┃           ┃           ┃  SIZE UP  ┃           ┃           ┃
            //             ┣━━━━━━━━━━━╋━━━━━━━━━━━╋━━━━━━━━━━━╋━━━━━━━━━━━╋━━━━━━━━━━━┫   ┣━━━━━━━━━━━╋━━━━━━━━━━━╋━━━━━━━━━━━╋━━━━━━━━━━━╋━━━━━━━━━━━┫
            //             ┃           ┃           ┃           ┃           ┃           ┃   ┃           ┃ SIZE LEFT ┃ SIZE DOWN ┃ SIZERIGHT ┃           ┃
            // ┏━━━━━━━━━━━╋━━━━━━━━━━━╋━━━━━━━━━━━╋━━━━━━━━━━━╋━━━━━━━━━━━╋━━━━━━━━━━━┫   ┣━━━━━━━━━━━╋━━━━━━━━━━━╋━━━━━━━━━━━╋━━━━━━━━━━━╋━━━━━━━━━━━╋━━━━━━━━━━━┓
            // ┃           ┃           ┃           ┃           ┃           ┃           ┃   ┃           ┃           ┃           ┃           ┃           ┃           ┃
            // ┗━━━━━━━━━━━┻━━━━━━━━━━━┻━━━━━━━━━━━╋━━━━━━━━━━━╋━━━━━━━━━━━╋━━━━━━━━━━━┫   ┣━━━━━━━━━━━╋━━━━━━━━━━━╋━━━━━━━━━━━╋━━━━━━━━━━━┻━━━━━━━━━━━┻━━━━━━━━━━━┛
            //                                     ┃           ┃           ┃           ┃   ┃           ┃           ┃           ┃
            //                                     ┗━━━━━━━━━━━┻━━━━━━━━━━━┻━━━━━━━━━━━┛   ┗━━━━━━━━━━━┻━━━━━━━━━━━┻━━━━━━━━━━━┛

            bindings = <
        &none   &none  &none  &none   &none     &none   &none          &kp LG(LS(EQUAL))  &none          &none
        &none   &none  &none  &none   &none     &none   &kp LG(MINUS)  &kp LG(LS(MINUS))  &kp LG(EQUAL)  &none
&trans  &trans  &none  &none  &none   &none     &none   &none          &none              &none          &none  &none
                       &to 0  &trans  &trans    &trans  &trans         &trans
            >;
        };

        // ▄▄▄▄▄▄▄▄▄▄▄▄▄▄▄▄▄▄▄▄▄▄▄▄▄▄▄▄▄▄▄▄▄▄▄▄▄▄▄▄▄▄▄▄▄▄▄▄▄▄▄▄▄▄▄▄▄▄▄▄▄▄▄▄▄▄▄▄▄▄▄▄▄▄▄▄▄▄▄▄▄▄▄▄▄▄▄▄▄▄▄▄▄▄▄▄▄▄▄▄▄▄▄▄▄▄▄▄▄▄▄▄▄▄▄▄▄▄▄▄▄▄▄▄▄▄▄▄▄▄▄▄▄▄▄▄▄▄▄▄▄▄▄▄▄▄▄▄▄

        norway_layer {
            // ┏━━━━━━━━━━━━━━━━━━━━━━━━━━━━━━━━━━━━━━━┓

            label = "NORW";

            // ┗━━━━━━━━━━━━━━━━━━━━━━━━━━━━━━━━━━━━━━━┛
            //             ┏━━━━━━━━━━━┳━━━━━━━━━━━┳━━━━━━━━━━━┳━━━━━━━━━━━┳━━━━━━━━━━━┓   ┏━━━━━━━━━━━┳━━━━━━━━━━━┳━━━━━━━━━━━┳━━━━━━━━━━━┳━━━━━━━━━━━┓
            //             ┃           ┃           ┃           ┃           ┃           ┃   ┃           ┃           ┃           ┃      Å    ┃           ┃
            //             ┣━━━━━━━━━━━╋━━━━━━━━━━━╋━━━━━━━━━━━╋━━━━━━━━━━━╋━━━━━━━━━━━┫   ┣━━━━━━━━━━━╋━━━━━━━━━━━╋━━━━━━━━━━━╋━━━━━━━━━━━╋━━━━━━━━━━━┫
            //             ┃           ┃           ┃           ┃           ┃           ┃   ┃           ┃           ┃     Ø     ┃      Æ    ┃           ┃
            // ┏━━━━━━━━━━━╋━━━━━━━━━━━╋━━━━━━━━━━━╋━━━━━━━━━━━╋━━━━━━━━━━━╋━━━━━━━━━━━┫   ┣━━━━━━━━━━━╋━━━━━━━━━━━╋━━━━━━━━━━━╋━━━━━━━━━━━╋━━━━━━━━━━━╋━━━━━━━━━━━┓
            // ┃           ┃           ┃           ┃           ┃           ┃           ┃   ┃           ┃           ┃           ┃           ┃           ┃           ┃
            // ┗━━━━━━━━━━━┻━━━━━━━━━━━┻━━━━━━━━━━━╋━━━━━━━━━━━╋━━━━━━━━━━━╋━━━━━━━━━━━┫   ┣━━━━━━━━━━━╋━━━━━━━━━━━╋━━━━━━━━━━━╋━━━━━━━━━━━┻━━━━━━━━━━━┻━━━━━━━━━━━┛
            //                                     ┃           ┃           ┃           ┃   ┃           ┃           ┃           ┃
            //                                     ┗━━━━━━━━━━━┻━━━━━━━━━━━┻━━━━━━━━━━━┛   ┗━━━━━━━━━━━┻━━━━━━━━━━━┻━━━━━━━━━━━┛

            bindings = <
        &trans  &trans  &trans  &trans  &trans    &trans  &trans  &trans     &nor_aa    &trans
        &trans  &trans  &trans  &trans  &trans    &trans  &trans  &kp RA(O)  &kp RA(A)  &trans
&trans  &trans  &trans  &trans  &trans  &trans    &trans  &trans  &trans     &trans     &trans  &trans
                        &to 0   &trans  &trans    &trans  &trans  &trans
            >;
        };

        // ▄▄▄▄▄▄▄▄▄▄▄▄▄▄▄▄▄▄▄▄▄▄▄▄▄▄▄▄▄▄▄▄▄▄▄▄▄▄▄▄▄▄▄▄▄▄▄▄▄▄▄▄▄▄▄▄▄▄▄▄▄▄▄▄▄▄▄▄▄▄▄▄▄▄▄▄▄▄▄▄▄▄▄▄▄▄▄▄▄▄▄▄▄▄▄▄▄▄▄▄▄▄▄▄▄▄▄▄▄▄▄▄▄▄▄▄▄▄▄▄▄▄▄▄▄▄▄▄▄▄▄▄▄▄▄▄▄▄▄▄▄▄▄▄▄▄▄▄▄

        select_layer {
            // ┏━━━━━━━━━━━━━━━━━━━━━━━━━━━━━━━━━━━━━━━┓

            label = "SELC";

            // ┗━━━━━━━━━━━━━━━━━━━━━━━━━━━━━━━━━━━━━━━┛
            //             ┏━━━━━━━━━━━┳━━━━━━━━━━━┳━━━━━━━━━━━┳━━━━━━━━━━━┳━━━━━━━━━━━┓   ┏━━━━━━━━━━━┳━━━━━━━━━━━┳━━━━━━━━━━━┳━━━━━━━━━━━┳━━━━━━━━━━━┓
            //             ┃  DEL TOP  ┃ DEL HOME  ┃           ┃ DEL END   ┃  DEL BTTM ┃   ┃  SEL TOP  ┃ SEL HOME  ┃           ┃ SEL END   ┃ SEL BTTM  ┃
            //             ┣━━━━━━━━━━━╋━━━━━━━━━━━╋━━━━━━━━━━━╋━━━━━━━━━━━╋━━━━━━━━━━━┫   ┣━━━━━━━━━━━╋━━━━━━━━━━━╋━━━━━━━━━━━╋━━━━━━━━━━━╋━━━━━━━━━━━┫
            //             ┃           ┃ DEL LEFT  ┃           ┃ DEL RIGHT ┃           ┃   ┃           ┃ SEL LEFT  ┃           ┃ SEL RIGHT ┃           ┃
            // ┏━━━━━━━━━━━╋━━━━━━━━━━━╋━━━━━━━━━━━╋━━━━━━━━━━━╋━━━━━━━━━━━╋━━━━━━━━━━━┫   ┣━━━━━━━━━━━╋━━━━━━━━━━━╋━━━━━━━━━━━╋━━━━━━━━━━━╋━━━━━━━━━━━╋━━━━━━━━━━━┓
            // ┃           ┃           ┃           ┃           ┃ DEL BTTM  ┃           ┃   ┃           ┃           ┃           ┃ SEL BTTM  ┃           ┃           ┃
            // ┗━━━━━━━━━━━┻━━━━━━━━━━━┻━━━━━━━━━━━╋━━━━━━━━━━━╋━━━━━━━━━━━╋━━━━━━━━━━━┫   ┣━━━━━━━━━━━╋━━━━━━━━━━━╋━━━━━━━━━━━╋━━━━━━━━━━━┻━━━━━━━━━━━┻━━━━━━━━━━━┛
            //                                     ┃           ┃           ┃   TERM    ┃   ┃           ┃   TERM    ┃           ┃
            //                                     ┗━━━━━━━━━━━┻━━━━━━━━━━━┻━━━━━━━━━━━┛   ┗━━━━━━━━━━━┻━━━━━━━━━━━┻━━━━━━━━━━━┛

            bindings = <
        &mc_csldl HOME  &mc_sldl HOME  &none  &mc_sldl END   &mc_csldl END    &kp LC(LS(HOME))  &kp LS(HOME)      &none   &kp LS(END)        &kp LC(LS(END))
        &none           &kp LC(BSPC)   &none  &kp LC(DEL)    &none            &none             &kp LC(LS(LEFT))  &none   &kp LC(LS(RIGHT))  &none
&trans  &none           &none          &none  &mc_csldl END  &none            &none             &none             &none   &kp LC(LS(END))    &none            &none
                                       &to 0  &trans         &mo 11           &trans            &mo 11            &trans
            >;
        };

        // ▄▄▄▄▄▄▄▄▄▄▄▄▄▄▄▄▄▄▄▄▄▄▄▄▄▄▄▄▄▄▄▄▄▄▄▄▄▄▄▄▄▄▄▄▄▄▄▄▄▄▄▄▄▄▄▄▄▄▄▄▄▄▄▄▄▄▄▄▄▄▄▄▄▄▄▄▄▄▄▄▄▄▄▄▄▄▄▄▄▄▄▄▄▄▄▄▄▄▄▄▄▄▄▄▄▄▄▄▄▄▄▄▄▄▄▄▄▄▄▄▄▄▄▄▄▄▄▄▄▄▄▄▄▄▄▄▄▄▄▄▄▄▄▄▄▄▄▄▄

        terminal_layer {
            // ┏━━━━━━━━━━━━━━━━━━━━━━━━━━━━━━━━━━━━━━━┓

            label = "TERM";

            // ┗━━━━━━━━━━━━━━━━━━━━━━━━━━━━━━━━━━━━━━━┛
            //             ┏━━━━━━━━━━━┳━━━━━━━━━━━┳━━━━━━━━━━━┳━━━━━━━━━━━┳━━━━━━━━━━━┓   ┏━━━━━━━━━━━┳━━━━━━━━━━━┳━━━━━━━━━━━┳━━━━━━━━━━━┳━━━━━━━━━━━┓
            //             ┃           ┃ DEL HOME  ┃           ┃ DEL END   ┃           ┃   ┃           ┃  GO HOME  ┃           ┃  GO END   ┃           ┃
            //             ┣━━━━━━━━━━━╋━━━━━━━━━━━╋━━━━━━━━━━━╋━━━━━━━━━━━╋━━━━━━━━━━━┫   ┣━━━━━━━━━━━╋━━━━━━━━━━━╋━━━━━━━━━━━╋━━━━━━━━━━━╋━━━━━━━━━━━┫
            //             ┃           ┃ DEL LEFT  ┃           ┃ DEL RIGHT ┃           ┃   ┃           ┃  GO LEFT  ┃           ┃  GO RIGHT ┃           ┃
            // ┏━━━━━━━━━━━╋━━━━━━━━━━━╋━━━━━━━━━━━╋━━━━━━━━━━━╋━━━━━━━━━━━╋━━━━━━━━━━━┫   ┣━━━━━━━━━━━╋━━━━━━━━━━━╋━━━━━━━━━━━╋━━━━━━━━━━━╋━━━━━━━━━━━╋━━━━━━━━━━━┓
            // ┃           ┃           ┃           ┃           ┃           ┃           ┃   ┃           ┃           ┃           ┃           ┃           ┃           ┃
            // ┗━━━━━━━━━━━┻━━━━━━━━━━━┻━━━━━━━━━━━╋━━━━━━━━━━━╋━━━━━━━━━━━╋━━━━━━━━━━━┫   ┣━━━━━━━━━━━╋━━━━━━━━━━━╋━━━━━━━━━━━╋━━━━━━━━━━━┻━━━━━━━━━━━┻━━━━━━━━━━━┛
            //                                     ┃           ┃           ┃           ┃   ┃           ┃           ┃           ┃
            //                                     ┗━━━━━━━━━━━┻━━━━━━━━━━━┻━━━━━━━━━━━┛   ┗━━━━━━━━━━━┻━━━━━━━━━━━┻━━━━━━━━━━━┛

            bindings = <
        &none  &kp LC(U)  &none  &kp LC(K)  &none     &none   &kp LC(A)      &none          &kp LC(E)      &none
        &none  &kp LC(W)  &none  &kp LA(D)  &none     &none   &kp LA(B)      &none          &kp LA(F)      &none
&trans  &none  &none      &none  &none      &none     &none   &kp LA(LC(A))  &kp LA(LC(D))  &kp LA(LC(R))  &none  &none
                          &to 0  &trans     &trans    &trans  &trans         &trans
            >;
        };

        // ▄▄▄▄▄▄▄▄▄▄▄▄▄▄▄▄▄▄▄▄▄▄▄▄▄▄▄▄▄▄▄▄▄▄▄▄▄▄▄▄▄▄▄▄▄▄▄▄▄▄▄▄▄▄▄▄▄▄▄▄▄▄▄▄▄▄▄▄▄▄▄▄▄▄▄▄▄▄▄▄▄▄▄▄▄▄▄▄▄▄▄▄▄▄▄▄▄▄▄▄▄▄▄▄▄▄▄▄▄▄▄▄▄▄▄▄▄▄▄▄▄▄▄▄▄▄▄▄▄▄▄▄▄▄▄▄▄▄▄▄▄▄▄▄▄▄▄▄▄

        qwerty_layer {
            // ┏━━━━━━━━━━━━━━━━━━━━━━━━━━━━━━━━━━━━━━━┓

            label = "QWER";

            // ┗━━━━━━━━━━━━━━━━━━━━━━━━━━━━━━━━━━━━━━━┛
            //             ┏━━━━━━━━━━━┳━━━━━━━━━━━┳━━━━━━━━━━━┳━━━━━━━━━━━┳━━━━━━━━━━━┓   ┏━━━━━━━━━━━┳━━━━━━━━━━━┳━━━━━━━━━━━┳━━━━━━━━━━━┳━━━━━━━━━━━┓
            //             ┃     Q     ┃     W     ┃     E     ┃     R     ┃     T     ┃   ┃     Y     ┃     U     ┃    I      ┃     O     ┃     P     ┃
            //             ┣━━━━━━━━━━━╋━━━━━━━━━━━╋━━━━━━━━━━━╋━━━━━━━━━━━╋━━━━━━━━━━━┫   ┣━━━━━━━━━━━╋━━━━━━━━━━━╋━━━━━━━━━━━╋━━━━━━━━━━━╋━━━━━━━━━━━┫
            //             ┃     A     ┃     S     ┃     D     ┃     F     ┃           ┃   ┃     H     ┃     J     ┃     K     ┃     L     ┃     '     ┃
            // ┏━━━━━━━━━━━╋━━━━━━━━━━━╋━━━━━━━━━━━╋━━━━━━━━━━━╋━━━━━━━━━━━╋━━━━━━━━━━━┫   ┣━━━━━━━━━━━╋━━━━━━━━━━━╋━━━━━━━━━━━╋━━━━━━━━━━━╋━━━━━━━━━━━╋━━━━━━━━━━━┓
            // ┃   LSHFT   ┃           ┃           ┃           ┃     V     ┃     B     ┃   ┃     N     ┃     M     ┃           ┃           ┃           ┃    CTRL   ┃
            // ┗━━━━━━━━━━━┻━━━━━━━━━━━┻━━━━━━━━━━━╋━━━━━━━━━━━╋━━━━━━━━━━━╋━━━━━━━━━━━┫   ┣━━━━━━━━━━━╋━━━━━━━━━━━╋━━━━━━━━━━━╋━━━━━━━━━━━┻━━━━━━━━━━━┻━━━━━━━━━━━┛
            //                                     ┃           ┃   SPACE   ┃           ┃   ┃           ┃           ┃           ┃
            //                                     ┗━━━━━━━━━━━┻━━━━━━━━━━━┻━━━━━━━━━━━┛   ┗━━━━━━━━━━━┻━━━━━━━━━━━┻━━━━━━━━━━━┛

            bindings = <
           &kp Q   &kp W   &kp E     &kp R      &kp T     &kp Y   &kp U   &kp I      &kp O    &kp P
           &kp A   &kp S   &kp D     &kp F      &trans    &kp H   &kp J   &kp K      &kp L    &kp SQT
&kp LSHFT  &trans  &trans  &trans    &kp V      &kp B     &kp N   &kp M   &kp COMMA  &kp DOT  &trans   &kp LCTRL
                           &td_base  &kp SPACE  &trans    &trans  &trans  &trans
            >;
        };

        // ▄▄▄▄▄▄▄▄▄▄▄▄▄▄▄▄▄▄▄▄▄▄▄▄▄▄▄▄▄▄▄▄▄▄▄▄▄▄▄▄▄▄▄▄▄▄▄▄▄▄▄▄▄▄▄▄▄▄▄▄▄▄▄▄▄▄▄▄▄▄▄▄▄▄▄▄▄▄▄▄▄▄▄▄▄▄▄▄▄▄▄▄▄▄▄▄▄▄▄▄▄▄▄▄▄▄▄▄▄▄▄▄▄▄▄▄▄▄▄▄▄▄▄▄▄▄▄▄▄▄▄▄▄▄▄▄▄▄▄▄▄▄▄▄▄▄▄▄▄

        game_layer {
            // ┏━━━━━━━━━━━━━━━━━━━━━━━━━━━━━━━━━━━━━━━┓

            label = "GAME";

            // ┗━━━━━━━━━━━━━━━━━━━━━━━━━━━━━━━━━━━━━━━┛
            //             ┏━━━━━━━━━━━┳━━━━━━━━━━━┳━━━━━━━━━━━┳━━━━━━━━━━━┳━━━━━━━━━━━┓   ┏━━━━━━━━━━━┳━━━━━━━━━━━┳━━━━━━━━━━━┳━━━━━━━━━━━┳━━━━━━━━━━━┓
            //             ┃     Q     ┃     W     ┃     F     ┃     P     ┃     B     ┃   ┃     J     ┃     L     ┃     O     ┃     Y     ┃     '     ┃
            //             ┣━━━━━━━━━━━╋━━━━━━━━━━━╋━━━━━━━━━━━╋━━━━━━━━━━━╋━━━━━━━━━━━┫   ┣━━━━━━━━━━━╋━━━━━━━━━━━╋━━━━━━━━━━━╋━━━━━━━━━━━╋━━━━━━━━━━━┫
            //             ┃     A     ┃     R     ┃     S     ┃     T     ┃     G     ┃   ┃     M     ┃     N     ┃     E     ┃     I     ┃     U     ┃
            // ┏━━━━━━━━━━━╋━━━━━━━━━━━╋━━━━━━━━━━━╋━━━━━━━━━━━╋━━━━━━━━━━━╋━━━━━━━━━━━┫   ┣━━━━━━━━━━━╋━━━━━━━━━━━╋━━━━━━━━━━━╋━━━━━━━━━━━╋━━━━━━━━━━━╋━━━━━━━━━━━┓
            // ┃    LSHFT  ┃     Z     ┃     X     ┃     C     ┃     D     ┃     V     ┃   ┃     K     ┃     H     ┃     ,     ┃     .     ┃     /     ┃   LCTRL    ┃
            // ┗━━━━━━━━━━━┻━━━━━━━━━━━┻━━━━━━━━━━━╋━━━━━━━━━━━╋━━━━━━━━━━━╋━━━━━━━━━━━┫   ┣━━━━━━━━━━━╋━━━━━━━━━━━╋━━━━━━━━━━━╋━━━━━━━━━━━┻━━━━━━━━━━━┻━━━━━━━━━━━┛
            //                                     ┃           ┃    SPC    ┃    TAB    ┃   ┃   ENTER   ┃    BSPC   ┃    DEL    ┃
            //                                     ┗━━━━━━━━━━━┻━━━━━━━━━━━┻━━━━━━━━━━━┛   ┗━━━━━━━━━━━┻━━━━━━━━━━━┻━━━━━━━━━━━┛

            bindings = <
           &kp Q  &kp W  &kp F     &kp P      &kp B     &kp J    &kp L     &kp O      &kp Y    &kp SQT
           &kp A  &kp R  &kp S     &kp T      &kp G     &kp M    &kp N     &kp E      &kp I    &kp U
&kp LSHFT  &kp Z  &kp X  &kp C     &kp D      &kp V     &kp K    &kp H     &kp COMMA  &kp DOT  &trans   &kp LCTRL
                         &td_base  &kp SPACE  &trans    &kp RET  &kp BSPC  &kp DEL
            >;
        };

        // ▄▄▄▄▄▄▄▄▄▄▄▄▄▄▄▄▄▄▄▄▄▄▄▄▄▄▄▄▄▄▄▄▄▄▄▄▄▄▄▄▄▄▄▄▄▄▄▄▄▄▄▄▄▄▄▄▄▄▄▄▄▄▄▄▄▄▄▄▄▄▄▄▄▄▄▄▄▄▄▄▄▄▄▄▄▄▄▄▄▄▄▄▄▄▄▄▄▄▄▄▄▄▄▄▄▄▄▄▄▄▄▄▄▄▄▄▄▄▄▄▄▄▄▄▄▄▄▄▄▄▄▄▄▄▄▄▄▄▄▄▄▄▄▄▄▄▄▄▄
        // ▄▄▄▄▄▄▄▄▄▄▄▄▄▄▄▄▄▄▄▄▄▄▄▄▄▄▄▄▄▄▄▄▄▄▄▄▄▄▄▄▄▄▄▄▄▄▄▄▄▄▄▄▄▄▄▄▄▄▄▄▄▄▄▄▄▄▄▄▄▄▄▄▄▄▄▄▄▄▄▄▄▄▄▄▄▄▄▄▄▄▄▄▄▄▄▄▄▄▄▄▄▄▄▄▄▄▄▄▄▄▄▄▄▄▄▄▄▄▄▄▄▄▄▄▄▄▄▄▄▄▄▄▄▄▄▄▄▄▄▄▄▄▄▄▄▄▄▄▄

        codesplit_layer {
            // ┏━━━━━━━━━━━━━━━━━━━━━━━━━━━━━━━━━━━━━━━┓

            label = "CSPL";

            // ┗━━━━━━━━━━━━━━━━━━━━━━━━━━━━━━━━━━━━━━━┛
            //             ┏━━━━━━━━━━━┳━━━━━━━━━━━┳━━━━━━━━━━━┳━━━━━━━━━━━┳━━━━━━━━━━━┓   ┏━━━━━━━━━━━┳━━━━━━━━━━━┳━━━━━━━━━━━┳━━━━━━━━━━━┳━━━━━━━━━━━┓
            //             ┃           ┃           ┃           ┃           ┃           ┃   ┃           ┃           ┃ SPLIT UP  ┃           ┃           ┃
            //             ┣━━━━━━━━━━━╋━━━━━━━━━━━╋━━━━━━━━━━━╋━━━━━━━━━━━╋━━━━━━━━━━━┫   ┣━━━━━━━━━━━╋━━━━━━━━━━━╋━━━━━━━━━━━╋━━━━━━━━━━━╋━━━━━━━━━━━┫
            //             ┃           ┃           ┃           ┃           ┃           ┃   ┃           ┃ SPLT LEFT ┃ SPLT DOWN ┃ SPLT RGHT ┃           ┃
            // ┏━━━━━━━━━━━╋━━━━━━━━━━━╋━━━━━━━━━━━╋━━━━━━━━━━━╋━━━━━━━━━━━╋━━━━━━━━━━━┫   ┣━━━━━━━━━━━╋━━━━━━━━━━━╋━━━━━━━━━━━╋━━━━━━━━━━━╋━━━━━━━━━━━╋━━━━━━━━━━━┓
            // ┃           ┃           ┃           ┃           ┃           ┃           ┃   ┃           ┃           ┃           ┃           ┃           ┃           ┃
            // ┗━━━━━━━━━━━┻━━━━━━━━━━━┻━━━━━━━━━━━╋━━━━━━━━━━━╋━━━━━━━━━━━╋━━━━━━━━━━━┫   ┣━━━━━━━━━━━╋━━━━━━━━━━━╋━━━━━━━━━━━╋━━━━━━━━━━━┻━━━━━━━━━━━┻━━━━━━━━━━━┛
            //                                     ┃           ┃           ┃           ┃   ┃           ┃           ┃           ┃
            //                                     ┗━━━━━━━━━━━┻━━━━━━━━━━━┻━━━━━━━━━━━┛   ┗━━━━━━━━━━━┻━━━━━━━━━━━┻━━━━━━━━━━━┛

            bindings = <
        &none  &none  &none  &none   &none     &none   &none         &codspl UP    &none          &none
        &none  &none  &none  &none   &none     &none   &codspl LEFT  &codspl DOWN  &codspl RIGHT  &none
&trans  &none  &none  &none  &none   &none     &none   &none         &none         &none          &none  &trans
                      &to 0  &trans  &trans    &trans  &trans        &trans
            >;
        };

        // ▄▄▄▄▄▄▄▄▄▄▄▄▄▄▄▄▄▄▄▄▄▄▄▄▄▄▄▄▄▄▄▄▄▄▄▄▄▄▄▄▄▄▄▄▄▄▄▄▄▄▄▄▄▄▄▄▄▄▄▄▄▄▄▄▄▄▄▄▄▄▄▄▄▄▄▄▄▄▄▄▄▄▄▄▄▄▄▄▄▄▄▄▄▄▄▄▄▄▄▄▄▄▄▄▄▄▄▄▄▄▄▄▄▄▄▄▄▄▄▄▄▄▄▄▄▄▄▄▄▄▄▄▄▄▄▄▄▄▄▄▄▄▄▄▄▄▄▄▄

        bluetooth_layer {
            // ┏━━━━━━━━━━━━━━━━━━━━━━━━━━━━━━━━━━━━━━━┓

            label = "BLUE";

            // ┗━━━━━━━━━━━━━━━━━━━━━━━━━━━━━━━━━━━━━━━┛
            //             ┏━━━━━━━━━━━┳━━━━━━━━━━━┳━━━━━━━━━━━┳━━━━━━━━━━━┳━━━━━━━━━━━┓   ┏━━━━━━━━━━━┳━━━━━━━━━━━┳━━━━━━━━━━━┳━━━━━━━━━━━┳━━━━━━━━━━━┓
            //             ┃ BT DISC 0 ┃ BT DISC 1 ┃ BT DISC 2 ┃ BT DISC 3 ┃           ┃   ┃ BTCLEARALL┃           ┃  BT NEXT  ┃           ┃           ┃
            //             ┣━━━━━━━━━━━╋━━━━━━━━━━━╋━━━━━━━━━━━╋━━━━━━━━━━━╋━━━━━━━━━━━┫   ┣━━━━━━━━━━━╋━━━━━━━━━━━╋━━━━━━━━━━━╋━━━━━━━━━━━╋━━━━━━━━━━━┫
            //             ┃ BT SEL 0  ┃ BT SEL 1  ┃ BT SEL 2  ┃ BT SEL 3  ┃           ┃   ┃  BT CLEAR ┃           ┃  BT PREV  ┃           ┃           ┃
            // ┏━━━━━━━━━━━╋━━━━━━━━━━━╋━━━━━━━━━━━╋━━━━━━━━━━━╋━━━━━━━━━━━╋━━━━━━━━━━━┫   ┣━━━━━━━━━━━╋━━━━━━━━━━━╋━━━━━━━━━━━╋━━━━━━━━━━━╋━━━━━━━━━━━╋━━━━━━━━━━━┓
            // ┃           ┃           ┃           ┃           ┃           ┃  OUT TOG  ┃   ┃           ┃           ┃           ┃           ┃           ┃           ┃
            // ┗━━━━━━━━━━━┻━━━━━━━━━━━┻━━━━━━━━━━━╋━━━━━━━━━━━╋━━━━━━━━━━━╋━━━━━━━━━━━┫   ┣━━━━━━━━━━━╋━━━━━━━━━━━╋━━━━━━━━━━━╋━━━━━━━━━━━┻━━━━━━━━━━━┻━━━━━━━━━━━┛
            //                                     ┃           ┃           ┃           ┃   ┃           ┃           ┃           ┃
            //                                     ┗━━━━━━━━━━━┻━━━━━━━━━━━┻━━━━━━━━━━━┛   ┗━━━━━━━━━━━┻━━━━━━━━━━━┻━━━━━━━━━━━┛

            bindings = <
       &none  &none  &none  &none   &out OUT_BLE    &bt BT_CLR      &none         &none         &none         &none
       &none  &none  &none  &none   &out OUT_USB    &bt BT_CLR_ALL  &bt BT_SEL 3  &bt BT_SEL 4  &none         &none
&none  &none  &none  &none  &none   &out OUT_TOG    &none           &bt BT_SEL 0  &bt BT_SEL 1  &bt BT_SEL 2  &none  &none
                     &to 0  &trans  &trans          &trans          &trans        &trans
            >;
        };

        // ▄▄▄▄▄▄▄▄▄▄▄▄▄▄▄▄▄▄▄▄▄▄▄▄▄▄▄▄▄▄▄▄▄▄▄▄▄▄▄▄▄▄▄▄▄▄▄▄▄▄▄▄▄▄▄▄▄▄▄▄▄▄▄▄▄▄▄▄▄▄▄▄▄▄▄▄▄▄▄▄▄▄▄▄▄▄▄▄▄▄▄▄▄▄▄▄▄▄▄▄▄▄▄▄▄▄▄▄▄▄▄▄▄▄▄▄▄▄▄▄▄▄▄▄▄▄▄▄▄▄▄▄▄▄▄▄▄▄▄▄▄▄▄▄▄▄▄▄▄
    };
};
